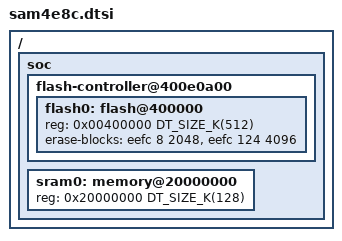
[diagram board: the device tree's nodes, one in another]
/*
 * Copyright (c) 2019 Gerson Fernando Budke
 *
 * SPDX-License-Identifier: Apache-2.0
 */

#include <mem.h>
#include <atmel/sam4e.dtsi>

/ {
	soc {
		flash-controller@400e0a00 {
			flash0: flash@400000 {
				reg = <0x00400000 DT_SIZE_K(512)>;
				erase-blocks = <&eefc 8 2048>, <&eefc 124 4096>;
			};
		};

		sram0: memory@20000000 {
			reg = <0x20000000 DT_SIZE_K(128)>;
		};
	};
};
